# USB0_COMMON_0_VBP2APB_WRAP_CONTROLLER_VBP_CORE_ADDR_MAP register map
Vendor: Texas Instruments
Registers are 32-bit, access per field, reset 0x0 unless marked. A register's access mark holds for its fields unless they carry their own. Offsets are as the file gives them; [hi:lo] are bit positions; {n}, {i} and the like mark numbered series.

## USB0_COMMON_0_VBP2APB_WRAP_CONTROLLER_VBP_CORE_ADDR_MAP (part 5 of 8)
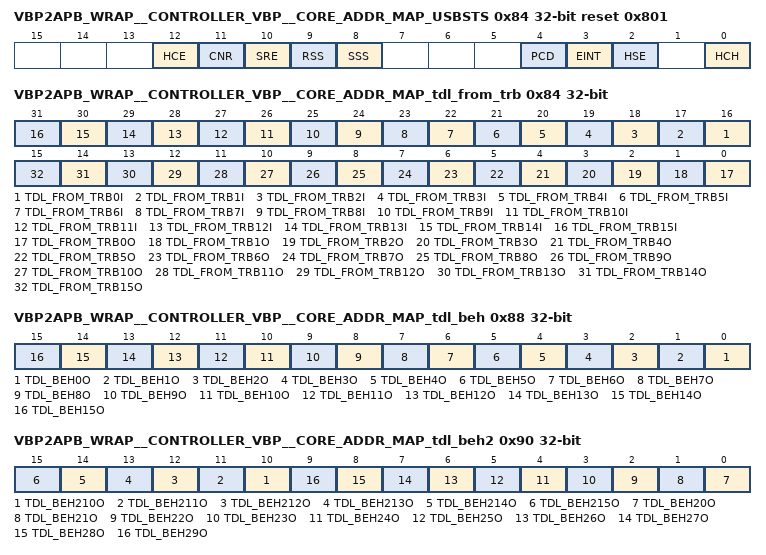
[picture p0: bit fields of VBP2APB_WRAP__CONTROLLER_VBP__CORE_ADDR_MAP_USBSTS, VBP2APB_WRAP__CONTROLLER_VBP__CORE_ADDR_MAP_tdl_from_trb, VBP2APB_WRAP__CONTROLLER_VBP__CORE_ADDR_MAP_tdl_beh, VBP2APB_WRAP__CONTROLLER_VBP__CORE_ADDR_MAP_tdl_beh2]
0x84 VBP2APB_WRAP__CONTROLLER_VBP__CORE_ADDR_MAP_USBSTS access not given reset 0x801
  [12] HCE ro — Host Controller Error [HCE], RO. Default = '0'. '0' = No internal xHC error conditions exist and '1' = Internal xHC error condition. This flag shall be set to indicate that an internal error condition has been detected which requires software to reset and reinitialize the xHC. Refer to section 4.24.1 of xHCI specification for more information.
  [11] CNR ro — Controller Not Ready [CNR], RO. Default = '1'. '0' = Ready and '1' = Not Ready. When this bit is '1', software shall not read or write any register of the xHC, other than those explicitly listed in the Design Specification section titled Register Accessibility. This flag is set by the xHC after a Chip Hardware Reset and cleared when the xHC is ready to begin accepting register reads or writes to all registers. This flag shall remain cleared ['0'] until the next Chip Hardware Reset.
  [10] SRE — Save/Restore Error [SRE], RW1C. Default = '0'. If an error occurs during a Save or Restore operation this bit shall be set to '1'. This bit shall be cleared to '0' when a Save or Restore operation is initiated or when written with '1'. Refer to section 4.23.2 of xHCI specification for more information. When this register is exposed by a Virtual Function [VF], the VMM determines the state of this bit as a function of the Save/Restore completion status for the selected VF. Refer to section 8 of xHCI specification for more information. (access R/W1TC)
  [9] RSS ro — Restore State Status [RSS], RO. Default = '0'. When the Controller Restore State [CRS] flag in the USBCMD register is written with '1' this bit shall be set to '1' and remain '1' while the xHC restores its internal state. When the Restore State operation is complete, this bit shall be cleared to '0'. Refer to section 4.23.2 of xHCI specification for more information. When this register is exposed by a Virtual Function [VF], the VMM determines the state of this bit as a function of the restoring the state for the selected VF. Refer to section 8 of xHCI specification for more information.
  [8] SSS ro — Save State Status [SSS], RO. Default = '0'. When the Controller Save State [CSS] flag in the USBCMD register is written with '1' this bit shall be set to '1' and remain '1' while the xHC saves its internal state. When the Save State operation is complete, this bit shall be cleared to '0'. Refer to section 4.23.2 of xHCI specification for more information. When this register is exposed by a Virtual Function [VF], the VMM determines the state of this bit as a function of the saving the state for the selected VF. Refer to section 8 of xHCI specification for more information.
  [4] PCD — Port Change Detect [PCD], RW1C. Default = '0'. The xHC sets this bit to a '1' when any port has a change bit transition from a '0' to a '1'. This bit is allowed to be maintained in the Aux Power well. Alternatively, it is also acceptable that on a D3 to D0 transition of the xHC, this bit is loaded with the OR of all of the PORTSC change bits. Refer to section 4.19.3 of xHCI specification. This bit provides system software an efficient means of determining if there has been Root Hub port activity. Refer to section 4.15.2.3 of xHCI specification for more information. When this register is exposed by a Virtual Function [VF], the VMM determines the state of this bit as a function of the Root Hub Ports associated with the Device Slots assigned to the selected VF. Refer to section 8 of xHCI specification for more information. (access R/W1TC)
  [3] EINT — Event Interrupt [EINT], RW1C. Default = '0'. The xHC sets this bit to '1' when the Interrupt Pending [IP] bit of any Interrupter transitions from '0' to '1'. Refer to section 7.1.2 of xHCI specification for use. Software that uses EINT shall clear it prior to clearing any IP flags. A race condition may occur if software clears the IP flags then clears the EINT flag, and between the operations another IP '0' to '1' transition occurs. In this case the new IP transition shall be lost. When this register is exposed by a Virtual Function [VF], this bit is the logical 'OR' of the IP bits for the Interrupters assigned to the selected VF. And it shall be cleared to '0' when all associated interrupter IP bits are cleared, i.e. all the VFs Interrupter Event Ring[s] are empty. Refer to section 8 of xHCI specification for more information (access R/W1TC)
  [2] HSE — Host System Error [HSE], RW1C. Default = '0'. The xHC sets this bit to '1' when a serious error is detected, either internal to the xHC or during a host system access involving the xHC module. [In a PCI system, conditions that set this bit to 1 include PCI Parity error, PCI Master Abort, and PCI Target Abort.] When this error occurs, the xHC clears the Run/Stop [R/S] bit in the USBCMD register to prevent further execution of the scheduled TDs. If the HSEE bit in the USBCMD register is a '1', the xHC shall also assert out-of-band error signaling to the host. Refer to section 4.10.2.6 of xHCI specification for more information. When this register is exposed by a Virtual Function [VF], the assertion of this bit affects all VFs and reflects the Host System Error state of the Physical Function [PF0]. Refer to section 8 of xHCI specification for more information. (access R/W1TC)
  [0] HCH ro — HCHalted [HCH], RO. Default = '1'. This bit is a '0' whenever the Run/Stop [R/S] bit is a '1'. The xHC sets this bit to '1' after it has stopped executing as a result of the Run/Stop [R/S] bit being cleared to '0', either by software or by the xHC hardware [e.g. internal error]. If this bit is '1', then SOFs, microSOFs, or Isochronous Timestamp Packets [ITP] shall not be generated by the xHC, and any received Transaction Packet shall be dropped. When this register is exposed by a Virtual Function [VF], this bit only reflects the Halted state of the xHC instance presented by the selected VF. Refer to section 8 of xHCI specification for more information.
0x84 VBP2APB_WRAP__CONTROLLER_VBP__CORE_ADDR_MAP_tdl_from_trb rw
  [n+16] TDL_FROM_TRB{n}I (n=0..15) — This field informs if support for automatic internal TDL calculation basing on the size provided in TRB for DMULT mode is enabled for selected Endpoint. To enable/disable this feature use the ENABLE_TDL_TRB/DISABLE_TDL_TRB bits in the USB_CONF2 register. When this option is enabled the TDL programming with EP_CMD.TDL+STDL is disabled, however read operation through this register can be performed. - 0 - controller doesn't support automatic internal TDL calculation - 1 - controller supports automatic internal TDL calculation This feature can be enabled only when controller supports it, i.e. when the USB_CAP1.TDL_FROM_TRB=1 and when DMULT mode for particular EP is set
  [n] TDL_FROM_TRB{n}O (n=0..15) — This field informs if support for automatic internal TDL calculation basing on the size provided in TRB for DMULT mode is enabled for selected Endpoint. To enable/disable this feature use the ENABLE_TDL_TRB/DISABLE_TDL_TRB bits in the USB_CONF2 register. When this option is enabled the TDL programming with EP_CMD.TDL+STDL is disabled, however read operation through this register can be performed. - 0 - controller doesn't support automatic internal TDL calculation - 1 - controller supports automatic internal TDL calculation This feature can be enabled only when controller supports it, i.e. when the USB_CAP1.TDL_FROM_TRB=1 and when DMULT mode for particular EP is set
0x88 VBP2APB_WRAP__CONTROLLER_VBP__CORE_ADDR_MAP_PAGESIZE ro reset 0x1
  [15:0] PAGESIZE — Page Size, RO. Default = Implementation defined. This field defines the page size supported by the xHC implementation. This xHC supports a page size of 2^[n+12] if bit n is Set. For example, if bit 0 is Set, the xHC supports 4k byte page sizes. For a Virtual Function, this register reflects the page size selected in the System Page Size field of the SR-IOV Extended Capability structure. For the Physical Function 0, this register reflects the implementation dependent default xHC page size. Various xHC resources reference PAGESIZE to describe their minimum alignment requirements. The maximum possible page size is 128M.
0x88 VBP2APB_WRAP__CONTROLLER_VBP__CORE_ADDR_MAP_tdl_beh access not given
  [n] TDL_BEH{n}O rw (n=0..15) — TDL behavior configuration Bit. This register configures TDL behavior for selected Endpoint.
0x8C VBP2APB_WRAP__CONTROLLER_VBP__CORE_ADDR_MAP_DB_ASF_MEM_MASK rw reset 0xFFFFFFFF
  [31:0] DB_ASF_MEM_MASK — Debug Feature. 0-DISABLE/1-ENABLE ECC check for memories
0x8C VBP2APB_WRAP__CONTROLLER_VBP__CORE_ADDR_MAP_RSVDZ8C ro
0x8C VBP2APB_WRAP__CONTROLLER_VBP__CORE_ADDR_MAP_ep_tdl
  [10:0] TDL rw — This field can be used to update/read internal TDL counter when TDL_FROM_TRB mode is not enabled for specific Endpoint.Writing into this field any non-zero value, will result in adding to existing TDL value the new written value. A as the maximum accumulative value of TDL counter is 2047, so when new value is written, and a sum of existing value and new value exceeds 2047, then register is wrap around, e.g. adding value 10 to the existing 2040 will result a value 2 in the TDL register. Writing zero, reset TDL counter to zero. For more information see USBSS-DEV_design_specification document.
0x90 VBP2APB_WRAP__CONTROLLER_VBP__CORE_ADDR_MAP_RSVDZ90 ro
0x90 VBP2APB_WRAP__CONTROLLER_VBP__CORE_ADDR_MAP_tdl_beh2 access not given
  [n-200] TDL_BEH{n}O rw (n=210..215) — TDL behavior 2 configuration Bit. This register configures TDL behavior for selected Endpoint.
  [n-20] TDL_BEH{n}O rw (n=20..29) — TDL behavior 2 configuration Bit. This register configures TDL behavior for selected Endpoint.
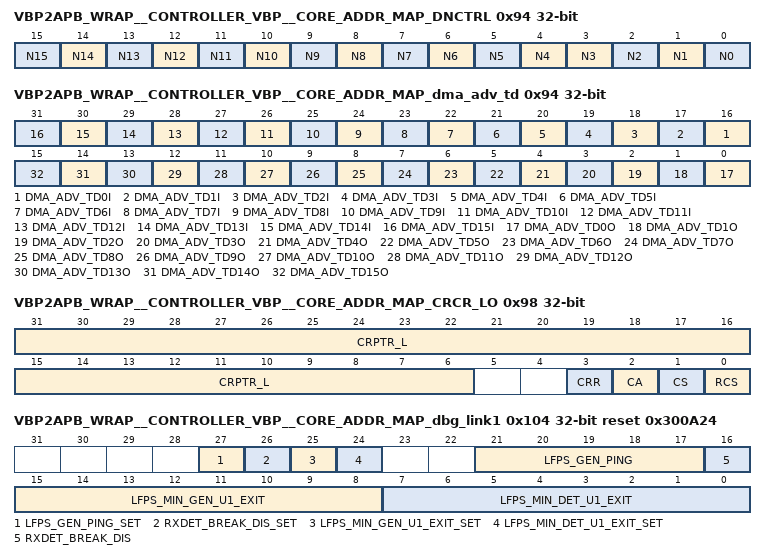
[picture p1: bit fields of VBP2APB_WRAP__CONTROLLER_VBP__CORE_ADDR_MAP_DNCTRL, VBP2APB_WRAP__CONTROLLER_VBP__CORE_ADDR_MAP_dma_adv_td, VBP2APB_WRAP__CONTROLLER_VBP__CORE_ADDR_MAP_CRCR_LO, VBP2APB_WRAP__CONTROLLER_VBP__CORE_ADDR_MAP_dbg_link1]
0x94 VBP2APB_WRAP__CONTROLLER_VBP__CORE_ADDR_MAP_DNCTRL
  [n] N{n} rw (n=4..15) — Notification Enable flag {n}
  [3] N3 rw — Notification Enable flag 3. BUS_INTERVAL_ADJUSTMENT_MESSAGE.
  [2] N2 rw — Notification Enable flag 2. LATENCY_TOLERANCE_MESSAGE.
  [1] N1 rw — Notification Enable flag 1
  [0] N0 rw — Notification Enable flag 0
0x94 VBP2APB_WRAP__CONTROLLER_VBP__CORE_ADDR_MAP_dma_adv_td rw
  [n+16] DMA_ADV_TD{n}I (n=0..15) — DMA Advance TD configuration Register for selected Endpoint.
  [n] DMA_ADV_TD{n}O (n=0..15) — DMA Advance TD configuration Register for selected Endpoint.
0x98 VBP2APB_WRAP__CONTROLLER_VBP__CORE_ADDR_MAP_CRCR_LO access not given
  [31:6] CRPTR_L rw — Command Ring Pointer Low, RW. Default = 0. This field defines low order bits of the initial value of the 64-bit Command Ring Dequeue Pointer. Writes to this field are ignored when Command Ring Running [CRR] = '1'. If the CRCR is written while the Command Ring is stopped [CCR = '0'], the value of this field shall be used to fetch the first Command TRB the next time the Host Controller Doorbell register is written with the DB Reason field set to Host Controller Command. If the CRCR is not written while the Command Ring is stopped [CCR = '0'] then the Command Ring shall begin fetching Command TRBs at the current value of the internal xHC Command Ring Dequeue Pointer. Reading this field always returns zero.
  [3] CRR ro — Command Ring Running [CRR], RO. Default = '0'. This flag is set to '1' if the Run/Stop [R/S] bit is '1' and the Host Controller Doorbell register is written with the DB Reason field set to Host Controller Command. It is cleared to '0' when the Command Ring is stopped after writing a '1' to the Command Stop [CS] or Command Abort [CA] flags, or if the R/S bit is cleared to '0'.
  [2] CA — Command Abort [CA], RW1S. Default = '0'. Writing a '1' to this bit shall immediately terminate the currently executing command, stop the Command Ring, and generate a Command Completion Event with the Completion Code set to Command Ring Stopped. Refer to section 4.6.1.2 of xHCI specification for more information on aborting a command. The next write to the Host Controller Doorbell with DB Reason field set to Host Controller Command shall restart the Command Ring operation. Writes to this flag are ignored by the xHC if Command Ring Running [CRR] = '0'. Reading this bit always returns '0'. (access R/W1TS)
  [1] CS — Command Stop [CS], RW1S. Default = '0'. Writing a '1' to this bit shall stop the operation of the Command Ring after the completion of the currently executing command, and generate a Command Completion Event with the Completion Code set to Command Ring Stopped and the Command TRB Pointer set to the current value of the Command Ring Dequeue Pointer. Refer to section 4.6.1.1 of xHCI specification for more information on stopping a command. The next write to the Host Controller Doorbell with DB Reason field set to Host Controller Command shall restart the Command Ring operation. Writes to this flag are ignored by the xHC if Command Ring Running [CRR] = '0'. Reading this bit shall always return '0'. (access R/W1TS)
  [0] RCS rw — Ring Cycle State [RCS], RW. This bit identifies the value of the xHC Consumer Cycle State [CCS] flag for the TRB referenced by the Command Ring Pointer. Refer to section 4.9.3 of xHCI specification for more information. Writes to this flag are ignored if Command Ring Running [CRR] is '1'. If the CRCR is written while the Command Ring is stopped [CRR = '0'], then the value of this flag shall be used to fetch the first Command TRB the next time the Host Controller Doorbell register is written with the DB Reason field set to Host Controller Command. If the CRCR is not written while the Command Ring is stopped [CRR = '0'], then the Command Ring shall begin fetching Command TRBs using the current value of the internal Command Ring CCS flag. Reading this flag always returns '0'.
0x9C VBP2APB_WRAP__CONTROLLER_VBP__CORE_ADDR_MAP_CRCR_HI rw
  [31:0] CRPTR_H — Command Ring Pointer High, RW. Default = 0. This field defines high order bits of the initial value of the 64-bit Command Ring Dequeue Pointer. Writes to this field are ignored when Command Ring Running [CRR] = '1'. If the CRCR is written while the Command Ring is stopped [CCR = '0'], the value of this field shall be used to fetch the first Command TRB the next time the Host Controller Doorbell register is written with the DB Reason field set to Host Controller Command. If the CRCR is not written while the Command Ring is stopped [CCR = '0'] then the Command Ring shall begin fetching Command TRBs at the current value of the internal xHC Command Ring Dequeue Pointer. Reading this field always returns zero.
0xA0 VBP2APB_WRAP__CONTROLLER_VBP__CORE_ADDR_MAP_RSVDZA0 ro
0xA4 VBP2APB_WRAP__CONTROLLER_VBP__CORE_ADDR_MAP_RSVDZA4 ro
0xA8 VBP2APB_WRAP__CONTROLLER_VBP__CORE_ADDR_MAP_RSVDZA8 ro
0xAC VBP2APB_WRAP__CONTROLLER_VBP__CORE_ADDR_MAP_RSVDZAC ro
0xB0 VBP2APB_WRAP__CONTROLLER_VBP__CORE_ADDR_MAP_DCBAAP_LO
  [31:6] DCBAAPTR_L rw — Device Context Base Address Array Pointer, RW. Default = 0. This field defines low order bits of the 64-bit base address of the Device Context Pointer Array. A table of address pointers that reference Device Context structures for the devices attached to the host.
0xB4 VBP2APB_WRAP__CONTROLLER_VBP__CORE_ADDR_MAP_DCBAAP_HI rw
  [31:0] DCBAAPTR_H — Device Context Base Address Array Pointer, RW. Default = 0. This field defines high order bits of the 64-bit base address of the Device Context Pointer Array. A table of address pointers that reference Device Context structures for the devices attached to the host.
0xB8 VBP2APB_WRAP__CONTROLLER_VBP__CORE_ADDR_MAP_CONFIG
  [7:0] MAXSLOTSEN rw — Max Device Slots Enabled [MaxSlotsEn], RW. Default = 0. This field specifies the maximum number of enabled Device Slots. Valid values are in the range of 0 to MaxSlots. Enabled Devices Slots are allocated contiguously. e.g. A value of 16 specifies that Device Slots 1 to 16 are active. A value of 0 disables all Device Slots. A disabled Device Slot shall not respond to Doorbell Register references. This field shall not be modified by software if the xHC is running [Run/Stop [R/S] = 1].
0xBC VBP2APB_WRAP__CONTROLLER_VBP__CORE_ADDR_MAP_RSVDZBC ro
0xC0 VBP2APB_WRAP__CONTROLLER_VBP__CORE_ADDR_MAP_RSVDZ_OP ro
0x100 VBP2APB_WRAP__CONTROLLER_VBP__CORE_ADDR_MAP_cfg_reg1 reset 0x38000
  [17:0] DEBOUNCER_CNT rw — This parameter defines the VBUS debouncer delay i.e. the time interval between the VBUS detection on device input and the start of using it internally. Resolution of this parameter is 128 ns. For simulation purposes it is recommended to set the value 1 [128ns] For synthesis purposes it is recommended to set the value 230000 [~30ms]
0x104 VBP2APB_WRAP__CONTROLLER_VBP__CORE_ADDR_MAP_dbg_link1 reset 0x300A24
  [27] LFPS_GEN_PING_SET wo — Set the LFPS_GEN_PING_SET value Writing '1' to this bit writes the LFPS_GEN_PING field value to the device. This bit is automatically cleared. Writing '0' has no effect.
  [26] RXDET_BREAK_DIS_SET wo — Set the RXDET_BREAK_DIS value Writing '1' to this bit writes the RXDET_BREAK_DIS field value to the device. This bit is automatically cleared. Writing '0' has no effect.
  [25] LFPS_MIN_GEN_U1_EXIT_SET wo — Set the LFPS_MIN_GEN_U1_EXIT value Writing '1' to this bit writes the LFPS_MIN_GEN_U1_EXIT field value to the device. This bit is automatically cleared. Writing '0' has no effect.
  [24] LFPS_MIN_DET_U1_EXIT_SET wo — Set the LFPS_MIN_DET_U1_EXIT value Writing '1' to this bit writes the LFPS_MIN_DET_U1_EXIT field value to the device. This bit is automatically cleared. Writing '0' has no effect.
  [21:17] LFPS_GEN_PING rw — LFPS_GEN_PING value This parameter configures the LFPS.Ping generation time as shown in the chapter 4. This field is saved to the device only when the field LFPS_GEN_PING_SET is set to '1' during write to the DBG_LINK1 register. Resolution of this parameter is 8 ns. For simulation purposes it is recommended to set the value 24 [~200ns] For synthesis purposes it is recommended to set the value 24 [~200ns]
  [16] RXDET_BREAK_DIS rw — RXDET_BREAK_DIS value This parameter configures terminating the Far-end Receiver termination detection sequence: '0': it is possible that USBSS_DEV will terminate Far-end receiver termination detection sequence '1': USBSS_DEV will not terminate Far-end receiver termination detection sequence The impact of the bit to the link behaviour is shown in chapter 4. This field is saved to the device only when the field RXDET_BREAK_DIS_SET is set to '1' during write to the DBG_LINK1 register.
  [15:8] LFPS_MIN_GEN_U1_EXIT rw — LFPS_MIN_GEN_U1_EXIT value This parameter configures the minimum time for phytxelecidle deassertion when LFPS.U1_Exit signalling is generated as shown in the chapter 4. This field is saved to the device only when the field LFPS_MIN_GEN_U1_EXIT_SET is set to '1' during write to the DBG_LINK1 register. Resolution of this parameter is 8 ns. For simulation purposes it is recommended to set the value 87 [~696ns] For synthesis purposes it is recommended to set the value 87 [~696ns]
  [7:0] LFPS_MIN_DET_U1_EXIT rw — LFPS_MIN_DET_U1_EXIT value This parameter configures the minimum time required for decoding the received LFPS as an LFPS.U1_Exit. Example is shown in the chapter 4. This field is saved to the device only when the field LFPS_MIN_DET_U1_EXIT_SET is set to '1' during write to the DBG_LINK1 register. Resolution of this parameter is 8 ns. For simulation purposes it is recommended to set the value 36 [~300ns]. For synthesis purposes it is recommended to set the value 36 [~300ns].
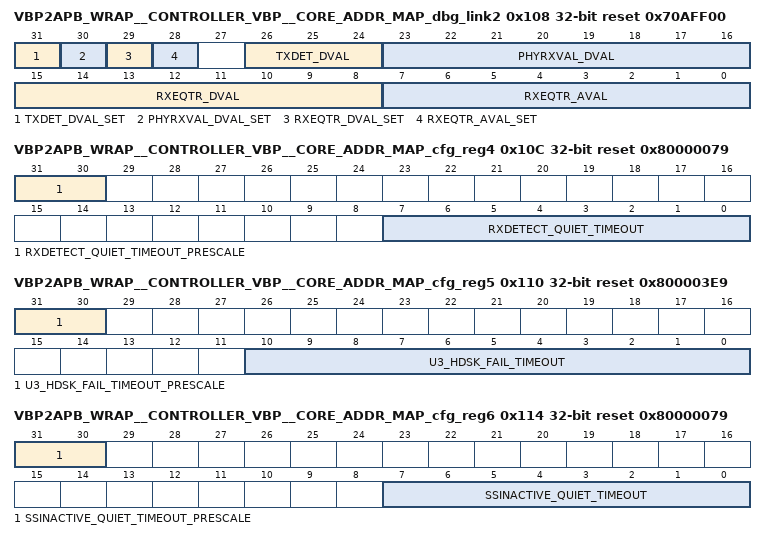
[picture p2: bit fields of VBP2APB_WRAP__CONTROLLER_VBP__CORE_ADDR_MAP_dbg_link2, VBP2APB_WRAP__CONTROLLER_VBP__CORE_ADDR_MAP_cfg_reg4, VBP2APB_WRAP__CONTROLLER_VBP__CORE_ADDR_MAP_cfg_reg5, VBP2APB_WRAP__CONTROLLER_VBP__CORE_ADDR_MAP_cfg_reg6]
0x108 VBP2APB_WRAP__CONTROLLER_VBP__CORE_ADDR_MAP_dbg_link2 reset 0x70AFF00
  [31] TXDET_DVAL_SET wo — Set the TXDET deassertion value Writing '1' to this bit writes the TXDET_DVAL field value to the device. This bit is automatically cleared. Writing '0' has no effect.
  [30] PHYRXVAL_DVAL_SET wo — Set the Phyrxvalid latency deassertion value Writing '1' to this bit writes the PHYRXVAL_DVAL field value to the device. This bit is automatically cleared. Writing '0' has no effect.0
  [29] RXEQTR_DVAL_SET wo — Set the rxeqtraining deassertion value Writing '1' to this bit writes the RXEQTR_DVAL field value to the device. This bit is automatically cleared. Writing '0' has no effect.
  [28] RXEQTR_AVAL_SET wo — Set the rxeqtraining assertion value Writing '1' to this bit writes the RXEQTR_AVAL field value to the device. This bit is automatically cleared. Writing '0' has no effect.
  [26:24] TXDET_DVAL rw — TXDET deassertion value This parameter configures the phytxdetrx_loop deassertion time after phystatus deassertion during Far-end receiver termination sequence as shown in the chapter 4. This field is saved to the device only when the field TXDET_DVAL_SET is set to '1' during write to the DBG_LINK2 register.
  [23:16] PHYRXVAL_DVAL rw — Phyrxvalid latency deassertion value This parameter enables extending internal phyrxdata and phyrxdatak validity as shown in the chapter 4. This field is saved to the device only when the field PHYRXVAL_DVAL_SET is set to '1' during write to the DBG_LINK2 register.
  [15:8] RXEQTR_DVAL rw — Rxeqtraining deassertion value This parameter configures phyrxeqtraining deasserting time as shown in the chapter 4. This field is saved to the device only when the field RXEQTR_DVAL_SET is set to '1' during write to the DBG_LINK2 register.
  [7:0] RXEQTR_AVAL rw — Rxeqtraining assertion value This parameter configures phyrxeqtraining asserting time as shown in the chapter 4. This field is saved to the device only when the field RXEQTR_AVAL_SET is set to '1' during write to the DBG_LINK2 register.
0x10C VBP2APB_WRAP__CONTROLLER_VBP__CORE_ADDR_MAP_cfg_reg4 reset 0x80000079
  [31:30] RXDETECT_QUIET_TIMEOUT_PRESCALE rw — PRESCALER for RXDETECT_QUIET_TIMEOUT : - 0x0 : 8ns [PHY pclk clock] - 0x1 : 1us - 0x2 : 100us - 0x3 : no clock - allows disabling certain timeout
  [7:0] RXDETECT_QUIET_TIMEOUT rw — RXDETECT_QUIET_TIMEOUT value Resolution of this parameter is selected by RXDETECT_QUIET_TIMEOUT_PRESCALE. For simulation purposes it is recommended to set the value: - 11*100us =~1ms [SystemC device ENV] - 13*1us =~12us [VIP based ENV] For synthesis purposes it is recommended to set the value 121*100us =~12ms
0x110 VBP2APB_WRAP__CONTROLLER_VBP__CORE_ADDR_MAP_cfg_reg5 reset 0x800003E9
  [31:30] U3_HDSK_FAIL_TIMEOUT_PRESCALE rw — PRESCALER for U3_HDSK_FAIL_TIMEOUT : - 0x0 : 8ns [PHY pclk clock] - 0x1 : 1us - 0x2 : 100us - 0x3 : no clock - allows disabling certain timeout
  [10:0] U3_HDSK_FAIL_TIMEOUT rw — U3_HDSK_FAIL_TIMEOUT value Resolution of this parameter is selected by U3_HDSK_FAIL_TIMEOUT_PRESCALE. For simulation purposes it is recommended to set the value: - 11*100us =~1ms [SystemC device ENV] - 11*100us =~1ms [VIP based ENV] For synthesis purposes it is recommended to set the value 1001*100us =~100ms
0x114 VBP2APB_WRAP__CONTROLLER_VBP__CORE_ADDR_MAP_cfg_reg6 reset 0x80000079
  [31:30] SSINACTIVE_QUIET_TIMEOUT_PRESCALE rw — PRESCALER for SSINACTIVE_QUIET_TIMEOUT value: - 0x0 : 8ns [PHY pclk clock] - 0x1 : 1us - 0x2 : 100us - 0x3 : no clock - allows disabling certain timeout
  [7:0] SSINACTIVE_QUIET_TIMEOUT rw — SSINACTIVE_QUIET_TIMEOUT value Resolution of this parameter is selected by SSINACTIVE_QUIET_TIMEOUT_PRESCALE. For simulation purposes it is recommended to set the value: - 11*100us =~1ms [SystemC device ENV] - 13*1us =~12us [VIP based ENV] For synthesis purposes it is recommended to set the value: - 121*100us =~12ms
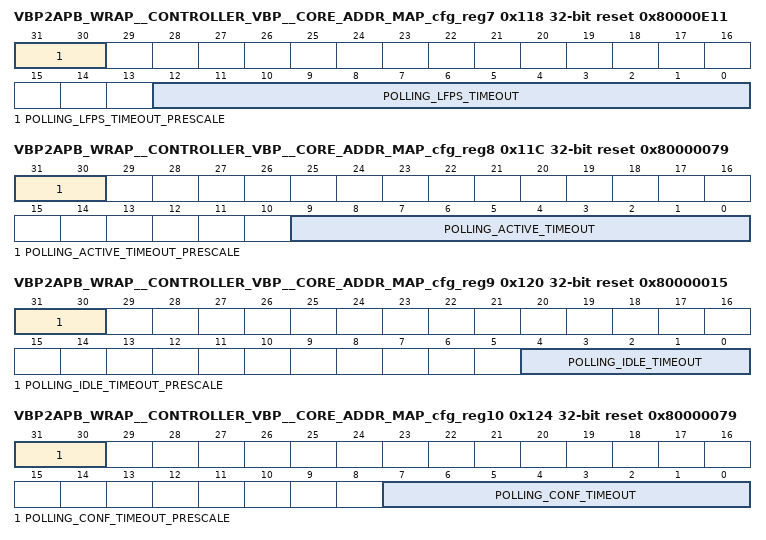
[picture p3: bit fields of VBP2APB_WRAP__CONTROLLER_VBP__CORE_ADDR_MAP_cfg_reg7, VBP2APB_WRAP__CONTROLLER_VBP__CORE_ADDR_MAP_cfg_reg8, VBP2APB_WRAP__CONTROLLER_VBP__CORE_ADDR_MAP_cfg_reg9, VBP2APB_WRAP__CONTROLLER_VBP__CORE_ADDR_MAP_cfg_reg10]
0x118 VBP2APB_WRAP__CONTROLLER_VBP__CORE_ADDR_MAP_cfg_reg7 reset 0x80000E11
  [31:30] POLLING_LFPS_TIMEOUT_PRESCALE rw — PRESCALER for POLLING_LFPS_TIMEOUT value: - 0x0 : 8ns [PHY pclk clock] - 0x1 : 1us - 0x2 : 100us - 0x3 : no clock - allows disabling certain timeout
  [12:0] POLLING_LFPS_TIMEOUT rw — POLLING_LFPS_TIMEOUT value Resolution of this parameter is selected by POLLING_LFPS_TIMEOUT_PRESCALE. For simulation purposes it is recommended to set the value: - 11*100us =~1ms [SystemC device ENV] - 481*1us =~480us [VIP based ENV] For synthesis purposes it is recommended to set the value: - 3601*100us =~360ms
0x11C VBP2APB_WRAP__CONTROLLER_VBP__CORE_ADDR_MAP_cfg_reg8 reset 0x80000079
  [31:30] POLLING_ACTIVE_TIMEOUT_PRESCALE rw — PRESCALER for POLLING_ACTIVE_TIMEOUT value: - 0x0 : 8ns [PHY pclk clock] - 0x1 : 1us - 0x2 : 100us - 0x3 : no clock - allows disabling certain timeout
  [9:0] POLLING_ACTIVE_TIMEOUT rw — POLLING_ACTIVE_TIMEOUT value Resolution of this parameter is selected by POLLING_ACTIVE_TIMEOUT_PRESCALE. For simulation purposes it is recommended to set the value: - 11*100us =~1ms [SystemC device ENV] - 31*1us =~30us [VIP based ENV] For synthesis purposes it is recommended to set the value: - 121*100us =~12ms
0x120 VBP2APB_WRAP__CONTROLLER_VBP__CORE_ADDR_MAP_cfg_reg9 reset 0x80000015
  [31:30] POLLING_IDLE_TIMEOUT_PRESCALE rw — PRESCALER for POLLING_IDLE_TIMEOUT value: - 0x0 : 8ns [PHY pclk clock] - 0x1 : 1us - 0x2 : 100us - 0x3 : no clock - allows disabling certain timeout
  [4:0] POLLING_IDLE_TIMEOUT rw — POLLING_IDLE_TIMEOUT value Resolution of this parameter is selected by POLLING_IDLE_TIMEOUT_PRESCALE. For simulation purposes it is recommended to set the value: - 21*100us =~2ms [SystemC device ENV] - 3*1us =~2us [VIP based ENV] For synthesis purposes it is recommended to set the value: - 21*100us =~2ms
0x124 VBP2APB_WRAP__CONTROLLER_VBP__CORE_ADDR_MAP_cfg_reg10 reset 0x80000079
  [31:30] POLLING_CONF_TIMEOUT_PRESCALE rw — PRESCALER for POLLING_CONF_TIMEOUT value: - 0x0 : 8ns [PHY pclk clock] - 0x1 : 1us - 0x2 : 100us - 0x3 : no clock - allows disabling certain timeout
  [7:0] POLLING_CONF_TIMEOUT rw — POLLING_CONF_TIMEOUT value Resolution of this parameter is selected by POLLING_CONF_TIMEOUT_PRESCALE. For simulation purposes it is recommended to set the value: - 11*100us =~1ms [SystemC device ENV] - 31*1us =~30us [VIP based ENV] For synthesis purposes it is recommended to set the value: - 121*100us =~12ms
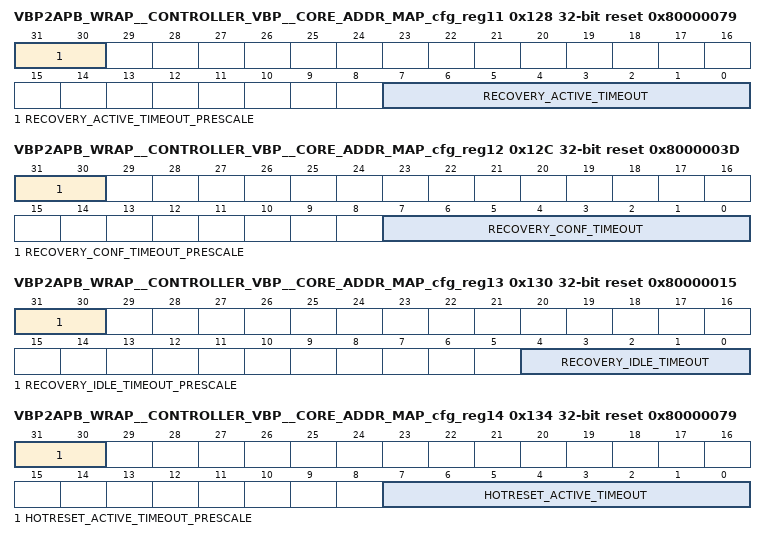
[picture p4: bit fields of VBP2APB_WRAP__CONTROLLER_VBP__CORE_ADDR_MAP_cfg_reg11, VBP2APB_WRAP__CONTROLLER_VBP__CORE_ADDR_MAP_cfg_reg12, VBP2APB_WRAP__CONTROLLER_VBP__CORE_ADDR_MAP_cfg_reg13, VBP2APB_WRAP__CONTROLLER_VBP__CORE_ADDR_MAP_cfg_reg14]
0x128 VBP2APB_WRAP__CONTROLLER_VBP__CORE_ADDR_MAP_cfg_reg11 reset 0x80000079
  [31:30] RECOVERY_ACTIVE_TIMEOUT_PRESCALE rw — PRESCALER for RECOVERY_ACTIVE_TIMEOUT value: - 0x0 : 8ns [PHY pclk clock] - 0x1 : 1us - 0x2 : 100us - 0x3 : no clock - allows disabling certain timeout
  [7:0] RECOVERY_ACTIVE_TIMEOUT rw — RECOVERY_ACTIVE_TIMEOUT value Resolution of this parameter is selected by RECOVERY_ACTIVE_TIMEOUT_PRESCALE. For simulation purposes it is recommended to set the value: - 11*100us =~1ms [SystemC device ENV] - 101*1us =~100us [VIP based ENV] For synthesis purposes it is recommended to set the value: - 121*100us =~12ms
0x12C VBP2APB_WRAP__CONTROLLER_VBP__CORE_ADDR_MAP_cfg_reg12 reset 0x8000003D
  [31:30] RECOVERY_CONF_TIMEOUT_PRESCALE rw — PRESCALER for RECOVERY_CONF_TIMEOUT value: - 0x0 : 8ns [PHY pclk clock] - 0x1 : 1us - 0x2 : 100us - 0x3 : no clock - allows disabling certain timeout
  [7:0] RECOVERY_CONF_TIMEOUT rw — RECOVERY_CONF_TIMEOUT value Resolution of this parameter is selected by RECOVERY_CONF_TIMEOUT_PRESCALE. For simulation purposes it is recommended to set the value: - 11*100us =~1ms [SystemC device ENV] - 101*1us =~100us [VIP based ENV] For synthesis purposes it is recommended to set the value: - 61*100us =~6ms
0x130 VBP2APB_WRAP__CONTROLLER_VBP__CORE_ADDR_MAP_cfg_reg13 reset 0x80000015
  [31:30] RECOVERY_IDLE_TIMEOUT_PRESCALE rw — PRESCALER for RECOVERY_IDLE_TIMEOUT value: - 0x0 : 8ns [PHY pclk clock] - 0x1 : 1us - 0x2 : 100us - 0x3 : no clock - allows disabling certain timeout
  [4:0] RECOVERY_IDLE_TIMEOUT rw — RECOVERY_IDLE_TIMEOUT value Resolution of this parameter is selected by RECOVERY_IDLE_TIMEOUT_PRESCALE. For simulation purposes it is recommended to set the value: - 21*100us =~2ms [SystemC device ENV] - 3*1us =~3us [VIP based ENV] For synthesis purposes it is recommended to set the value: - 21*100us =~2ms
0x134 VBP2APB_WRAP__CONTROLLER_VBP__CORE_ADDR_MAP_cfg_reg14 reset 0x80000079
  [31:30] HOTRESET_ACTIVE_TIMEOUT_PRESCALE rw — PRESCALER for HOTRESET_ACTIVE_TIMEOUT value: - 0x0 : 8ns [PHY pclk clock] - 0x1 : 1us - 0x2 : 100us - 0x3 : no clock - allows disabling certain timeout
  [7:0] HOTRESET_ACTIVE_TIMEOUT rw — HOTRESET_ACTIVE_TIMEOUT value Resolution of this parameter is selected by HOTRESET_ACTIVE_TIMEOUT_PRESCALE. For simulation purposes it is recommended to set the value: - 21*100us =~2ms [SystemC device ENV] - 13*1us =~13us [VIP based ENV] For synthesis purposes it is recommended to set the value: - 121*100us =~12ms
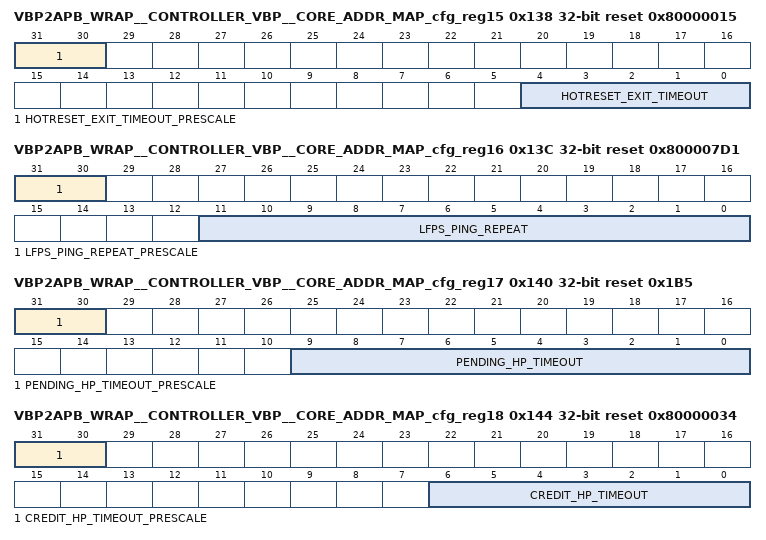
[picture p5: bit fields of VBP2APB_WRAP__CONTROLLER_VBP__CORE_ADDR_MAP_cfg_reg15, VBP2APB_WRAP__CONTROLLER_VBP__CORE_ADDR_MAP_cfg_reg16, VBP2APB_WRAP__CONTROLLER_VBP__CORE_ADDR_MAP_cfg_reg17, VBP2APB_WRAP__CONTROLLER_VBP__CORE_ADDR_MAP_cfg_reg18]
0x138 VBP2APB_WRAP__CONTROLLER_VBP__CORE_ADDR_MAP_cfg_reg15 reset 0x80000015
  [31:30] HOTRESET_EXIT_TIMEOUT_PRESCALE rw — PRESCALER for HOTRESET_EXIT_TIMEOUT value: - 0x0 : 8ns [PHY pclk clock] - 0x1 : 1us - 0x2 : 100us - 0x3 : no clock - allows disabling certain timeout
  [4:0] HOTRESET_EXIT_TIMEOUT rw — HOTRESET_EXIT_TIMEOUT value Resolution of this parameter is selected by HOTRESET_EXIT_TIMEOUT_PRESCALE. For simulation purposes it is recommended to set the value: - 21*100us =~2ms [SystemC device ENV] - 3*1us =~3us [VIP based ENV] For synthesis purposes it is recommended to set the value: - 21*100us =~2ms
0x13C VBP2APB_WRAP__CONTROLLER_VBP__CORE_ADDR_MAP_cfg_reg16 reset 0x800007D1
  [31:30] LFPS_PING_REPEAT_PRESCALE rw — PRESCALER for LFPS_PING_REPEAT value: - 0x0 : 8ns [PHY pclk clock] - 0x1 : 1us - 0x2 : 100us - 0x3 : no clock - allows disabling certain timeout
  [11:0] LFPS_PING_REPEAT rw — LFPS_PING_REPEAT value Resolution of this parameter is selected by LFPS_PING_REPEAT_PRESCALE. For simulation purposes it is recommended to set the value: - 6*100us =~0.5ms [SystemC device ENV] - 4*100us =~400us [VIP based ENV] For synthesis purposes it is recommended to set the value: - 2001*100us =~200ms
0x140 VBP2APB_WRAP__CONTROLLER_VBP__CORE_ADDR_MAP_cfg_reg17 reset 0x1B5
  [31:30] PENDING_HP_TIMEOUT_PRESCALE rw — PRESCALER for PENDING_HP_TIMEOUT value: - 0x0 : 8ns [PHY pclk clock] - 0x1 : 1us - 0x2 : 100us - 0x3 : no clock - allows disabling certain timeout
  [9:0] PENDING_HP_TIMEOUT rw — PENDING_HP_TIMEOUT value Resolution of this parameter is selected by PENDING_HP_TIMEOUT_PRESCALE. For simulation purposes it is recommended to set the value: - 437*8ns =~3.5us [SystemC device ENV] - 437*8ns =~3.5us [VIP based ENV] For synthesis purposes it is recommended to set the value: - 437*8ns =~3.5us
0x144 VBP2APB_WRAP__CONTROLLER_VBP__CORE_ADDR_MAP_cfg_reg18 reset 0x80000034
  [31:30] CREDIT_HP_TIMEOUT_PRESCALE rw — PRESCALER for CREDIT_HP_TIMEOUT value: - 0x0 : 8ns [PHY pclk clock] - 0x1 : 1us - 0x2 : 100us - 0x3 : no clock - allows disabling certain timeout
  [6:0] CREDIT_HP_TIMEOUT rw — CREDIT_HP_TIMEOUT value Resolution of this parameter is selected by CREDIT_HP_TIMEOUT_PRESCALE. For simulation purposes it is recommended to set the value: - 11*100us =~1ms [SystemC device ENV] - 11*100us =~1ms [VIP based ENV] For synthesis purposes it is recommended to set the value: - 52*100us =~5.1ms
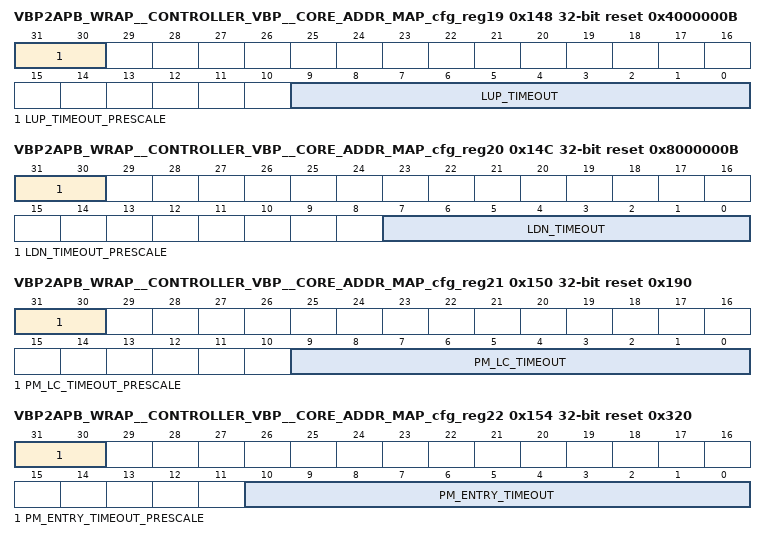
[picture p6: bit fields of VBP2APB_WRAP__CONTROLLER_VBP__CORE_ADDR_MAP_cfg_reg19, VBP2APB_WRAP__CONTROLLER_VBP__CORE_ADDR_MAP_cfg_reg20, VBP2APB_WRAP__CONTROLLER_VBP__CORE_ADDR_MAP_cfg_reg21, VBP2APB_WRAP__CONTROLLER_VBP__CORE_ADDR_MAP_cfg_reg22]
0x148 VBP2APB_WRAP__CONTROLLER_VBP__CORE_ADDR_MAP_cfg_reg19 reset 0x4000000B
  [31:30] LUP_TIMEOUT_PRESCALE rw — PRESCALER for LUP_TIMEOUT value: - 0x0 : 8ns [PHY pclk clock] - 0x1 : 1us - 0x2 : 100us - 0x3 : no clock - allows disabling certain timeout
  [9:0] LUP_TIMEOUT rw — LUP_TIMEOUT value Resolution of this parameter is selected by LUP_TIMEOUT_PRESCALE. For simulation purposes it is recommended to set the value: - 11*1us =~11us [SystemC device ENV] - 11*1us =~11us [VIP based ENV] For synthesis purposes it is recommended to set the value: - 11*1us =~11us
0x14C VBP2APB_WRAP__CONTROLLER_VBP__CORE_ADDR_MAP_cfg_reg20 reset 0x8000000B
  [31:30] LDN_TIMEOUT_PRESCALE rw — PRESCALER for LDN_TIMEOUT value: - 0x0 : 8ns [PHY pclk clock] - 0x1 : 1us - 0x2 : 100us - 0x3 : no clock - allows disabling certain timeout
  [7:0] LDN_TIMEOUT rw — LDN_TIMEOUT value Resolution of this parameter is selected by LDN_TIMEOUT_PRESCALE. For simulation purposes it is recommended to set the value: - 11*100us =~1ms [SystemC device ENV] - 129*1us =~129us [VIP based ENV] For synthesis purposes it is recommended to set the value: - 11*100us =~1ms
0x150 VBP2APB_WRAP__CONTROLLER_VBP__CORE_ADDR_MAP_cfg_reg21 reset 0x190
  [31:30] PM_LC_TIMEOUT_PRESCALE rw — PRESCALER for PM_LC_TIMEOUT value: - 0x0 : 8ns [PHY pclk clock] - 0x1 : 1us - 0x2 : 100us - 0x3 : no clock - allows disabling certain timeout
  [9:0] PM_LC_TIMEOUT rw — PM_LC_TIMEOUT value Resolution of this parameter is selected by PM_LC_TIMEOUT_PRESCALE. For simulation purposes it is recommended to set the value: - 400*8ns =~3.2us [SystemC device ENV] - 400*8ns =~3.2us [VIP based ENV] For synthesis purposes it is recommended to set the value: - 400*8ns =~3.2us
0x154 VBP2APB_WRAP__CONTROLLER_VBP__CORE_ADDR_MAP_cfg_reg22 reset 0x320
  [31:30] PM_ENTRY_TIMEOUT_PRESCALE rw — PRESCALER for PM_ENTRY_TIMEOUT value: - 0x0 : 8ns [PHY pclk clock] - 0x1 : 1us - 0x2 : 100us - 0x3 : no clock - allows disabling certain timeout
  [10:0] PM_ENTRY_TIMEOUT rw — PM_ENTRY_TIMEOUT value Resolution of this parameter is selected by PM_ENTRY_TIMEOUT_PRESCALE. For simulation purposes it is recommended to set the value: - 800*8ns =~6.4us [SystemC device ENV] - 800*8ns =~6.4us [VIP based ENV] For synthesis purposes it is recommended to set the value: - 800*8ns =~6.4us
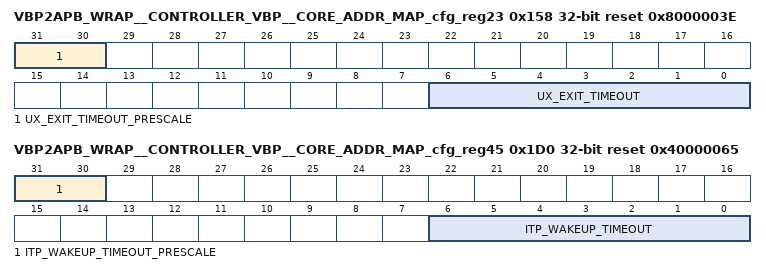
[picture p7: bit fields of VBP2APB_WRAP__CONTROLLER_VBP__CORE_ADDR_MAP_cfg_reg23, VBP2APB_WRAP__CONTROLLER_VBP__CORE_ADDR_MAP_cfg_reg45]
0x158 VBP2APB_WRAP__CONTROLLER_VBP__CORE_ADDR_MAP_cfg_reg23 reset 0x8000003E
  [31:30] UX_EXIT_TIMEOUT_PRESCALE rw — PRESCALER for UX_EXIT_TIMEOUT value: - 0x0 : 8ns [PHY pclk clock] - 0x1 : 1us - 0x2 : 100us - 0x3 : no clock - allows disabling certain timeout
  [6:0] UX_EXIT_TIMEOUT rw — UX_EXIT_TIMEOUT value Resolution of this parameter is selected by UX_EXIT_TIMEOUT_PRESCALE. For simulation purposes it is recommended to set the value: - 8*100us =~800us [SystemC device ENV] - 3*100us =~300us [VIP based ENV] For synthesis purposes it is recommended to set the value: - 62*100us =~6.2ms
0x15C VBP2APB_WRAP__CONTROLLER_VBP__CORE_ADDR_MAP_cfg_reg24 reset 0x243D58
  [22:0] LFPS_DET_RESET_MIN rw — LFPS_DET_RESET_MIN value Resolution of this parameter is 8 ns. For simulation purposes it is recommended to set the value 395833 [~3.16ms] For synthesis purposes it is recommended to set the value 2375000 [~19ms]
0x160 VBP2APB_WRAP__CONTROLLER_VBP__CORE_ADDR_MAP_cfg_reg25 reset 0xE4E1C0
  [23:0] LFPS_DET_RESET_MAX rw — LFPS_DET_RESET_MAX value Resolution of this parameter is 8 ns. For simulation purposes it is recommended to set the value 5000000 [~40ms] For synthesis purposes it is recommended to set the value 15000000 [~120ms]
0x164 VBP2APB_WRAP__CONTROLLER_VBP__CORE_ADDR_MAP_cfg_reg26 reset 0x4B
  [6:0] LFPS_DET_POLLING_MIN rw — LFPS_DET_POLLING_MIN value Resolution of this parameter is 8 ns. For simulation purposes it is recommended to set the value 75 [~0.6us] For synthesis purposes it is recommended to set the value 75 [~0.6us]
0x168 VBP2APB_WRAP__CONTROLLER_VBP__CORE_ADDR_MAP_cfg_reg27 reset 0xBB
  [7:0] LFPS_DET_POLLING_MAX rw — LFPS_DET_POLLING_MAX value Resolution of this parameter is 8 ns. For simulation purposes it is recommended to set the value 175 [~1.4us] For synthesis purposes it is recommended to set the value 175 [~1.4us]
0x16C VBP2APB_WRAP__CONTROLLER_VBP__CORE_ADDR_MAP_cfg_reg28 reset 0x4
  [2:0] LFPS_DET_PING_MIN rw — LFPS_DET_PING_MIN value Resolution of this parameter is 8 ns. For simulation purposes it is recommended to set the value 4 [~40ns] For synthesis purposes it is recommended to set the value 4 [~40ns]
0x170 VBP2APB_WRAP__CONTROLLER_VBP__CORE_ADDR_MAP_cfg_reg29 reset 0x17
  [4:0] LFPS_DET_PING_MAX rw — LFPS_DET_PING_MAX value Resolution of this parameter is 8 ns. For simulation purposes it is recommended to set the value 23 [~200ns] For synthesis purposes it is recommended to set the value 23 [~200ns]
0x174 VBP2APB_WRAP__CONTROLLER_VBP__CORE_ADDR_MAP_cfg_reg30 reset 0x24
  [5:0] LFPS_DET_U1EXIT_MIN rw — LFPS_DET_U1EXIT_MIN value Resolution of this parameter is 8 ns. For simulation purposes it is recommended to set the value 36 [~300ns] For synthesis purposes it is recommended to set the value 36 [~300ns]
0x178 VBP2APB_WRAP__CONTROLLER_VBP__CORE_ADDR_MAP_cfg_reg31 reset 0x6F
  [6:0] LFPS_DET_U1EXIT_MAX rw — LFPS_DET_U1EXIT_MAX value Resolution of this parameter is 8 ns. For simulation purposes it is recommended to set the value 111 [~900ns] For synthesis purposes it is recommended to set the value 111 [~900ns]
0x17C VBP2APB_WRAP__CONTROLLER_VBP__CORE_ADDR_MAP_cfg_reg32 reset 0x24
  [5:0] LFPS_DET_U2EXIT_MIN rw — LFPS_DET_U2EXIT_MIN value Resolution of this parameter is 8 ns. For simulation purposes it is recommended to set the value 36 [~300ns] For synthesis purposes it is recommended to set the value 36 [~300ns]
0x180 VBP2APB_WRAP__CONTROLLER_VBP__CORE_ADDR_MAP_cfg_reg33 reset 0x3D090
  [17:0] LFPS_DET_U2EXIT_MAX rw — LFPS_DET_U2EXIT_MAX value Resolution of this parameter is 8 ns. For simulation purposes it is recommended to set the value 250000 [~2ms] For synthesis purposes it is recommended to set the value 250000 [~2ms]
0x184 VBP2APB_WRAP__CONTROLLER_VBP__CORE_ADDR_MAP_cfg_reg34 reset 0x24
  [5:0] LFPS_DET_U3EXIT_MIN rw — LFPS_DET_U3EXIT_MIN value Resolution of this parameter is 8 ns. For simulation purposes it is recommended to set the value 36 [~300ns] For synthesis purposes it is recommended to set the value 36 [~300ns]
0x188 VBP2APB_WRAP__CONTROLLER_VBP__CORE_ADDR_MAP_cfg_reg35 reset 0x1312D0
  [20:0] LFPS_DET_U3EXIT_MAX rw — LFPS_DET_U3EXIT_MAX value Resolution of this parameter is 8 ns. For simulation purposes it is recommended to set the value 1250000 [~10ms] For synthesis purposes it is recommended to set the value 1250000 [~10ms]
0x1AC VBP2APB_WRAP__CONTROLLER_VBP__CORE_ADDR_MAP_cfg_reg36 reset 0x18
  [4:0] LFPS_GEN_PING rw — LFPS_GEN_PING value Resolution of this parameter is 8 ns. For simulation purposes it is recommended to set the value 24 [~200ns] For synthesis purposes it is recommended to set the value 24 [~200ns]
0x1B0 VBP2APB_WRAP__CONTROLLER_VBP__CORE_ADDR_MAP_cfg_reg37 reset 0x7D
  [7:0] LFPS_GEN_POLLING rw — LFPS_GEN_POLLING value Resolution of this parameter is 8 ns. For simulation purposes it is recommended to set the value 125 [~1us] For synthesis purposes it is recommended to set the value 125 [~1us]
0x1B4 VBP2APB_WRAP__CONTROLLER_VBP__CORE_ADDR_MAP_cfg_reg38 reset 0x3D090
  [17:0] LFPS_GEN_U1EXIT rw — LFPS_GEN_U1EXIT value Resolution of this parameter is 8 ns. For simulation purposes it is recommended to set the value 62500 [~500us] For synthesis purposes it is recommended to set the value 250000 [~2ms]
0x1B8 VBP2APB_WRAP__CONTROLLER_VBP__CORE_ADDR_MAP_cfg_reg39 reset 0x1312D0
  [20:0] LFPS_GEN_U3EXIT rw — LFPS_GEN_U3EXIT value Resolution of this parameter is 8 ns. For simulation purposes it is recommended to set the value 125000 [~1ms] For synthesis purposes it is recommended to set the value 1250000 [~10ms]
0x1BC VBP2APB_WRAP__CONTROLLER_VBP__CORE_ADDR_MAP_cfg_reg40 reset 0x1F
  [6:0] LFPS_MIN_GEN_U1EXIT rw — LFPS_MIN_GEN_U1EXIT value Resolution of this parameter is 8 ns. For simulation purposes it is recommended to set the value 87 [~696ns] For synthesis purposes it is recommended to set the value 87 [~696ns]
0x1C0 VBP2APB_WRAP__CONTROLLER_VBP__CORE_ADDR_MAP_cfg_reg41 reset 0x30D4
  [14:0] LFPS_MIN_GEN_U2EXIT rw — LFPS_MIN_GEN_U2EXIT value Resolution of this parameter is 8 ns. For simulation purposes it is recommended to set the value 12500 [~100us] For synthesis purposes it is recommended to set the value 12500 [~100us]
0x1C4 VBP2APB_WRAP__CONTROLLER_VBP__CORE_ADDR_MAP_cfg_reg42 reset 0x4E2
  [10:0] LFPS_POLLING_REPEAT rw — LFPS_POLLING_REPEAT value Resolution of this parameter is 8 ns. For simulation purposes it is recommended to set the value 1250 [~10us] For synthesis purposes it is recommended to set the value 1250 [~10us]
0x1C8 VBP2APB_WRAP__CONTROLLER_VBP__CORE_ADDR_MAP_cfg_reg43 reset 0x6D6
  [10:0] LFPS_POLLING_MAX_TREPEAT rw — LFPS_POLLING_MAX_TREPEAT value Resolution of this parameter is 8 ns. For simulation purposes it is recommended to set the value 1750 [~14us] For synthesis purposes it is recommended to set the value 1750 [~14us]
0x1CC VBP2APB_WRAP__CONTROLLER_VBP__CORE_ADDR_MAP_cfg_reg44 reset 0x2EC
  [10:0] LFPS_POLLING_MIN_TREPEAT rw — LFPS_POLLING_MIN_TREPEAT value Resolution of this parameter is 8 ns. For simulation purposes it is recommended to set the value 748 [~6us] For synthesis purposes it is recommended to set the value 748 [~6us]
0x1D0 VBP2APB_WRAP__CONTROLLER_VBP__CORE_ADDR_MAP_cfg_reg45 reset 0x40000065
  [31:30] ITP_WAKEUP_TIMEOUT_PRESCALE rw — PRESCALER for ITP_WAKEUP_TIMEOUT value: - 0x0 : 8ns [PHY pclk clock] - 0x1 : 1us - 0x2 : 100us - 0x3 : no clock - allows disabling certain timeout
  [6:0] ITP_WAKEUP_TIMEOUT rw — ITP_WAKEUP_TIMEOUT value Resolution of this parameter is selected by ITP_WAKEUP_TIMEOUT_PRESCALE. For simulation purposes it is recommended to set the value: - 101*1us =~100us [SystemC device ENV] - 101*1us =~100us [VIP based ENV] For synthesis purposes it is recommended to set the value: - 101*1us =~100us
0x1D4 VBP2APB_WRAP__CONTROLLER_VBP__CORE_ADDR_MAP_cfg_reg46 reset 0xFFFF
  [15:0] TSEQ_QUANTITY rw — TSEQ_QUANTITY value This parameter defines the number of TSEQ training sequences to be sent during Polling.RxEq state. For simulation purposes it is recommended to set the value 655 For synthesis purposes it is recommended to set the value 65535.
0x1D8 VBP2APB_WRAP__CONTROLLER_VBP__CORE_ADDR_MAP_cfg_reg47 reset 0x7D001
  [19:0] ERDY_TIMEOUT_CNT rw — ERDY_TIMEOUT_CNT value Resolution of this parameter is 1 us. For simulation purposes it is recommended to set the value 16 [~15 us] For synthesis purposes it is recommended to set the value ~512001 [~512ms]
0x1DC VBP2APB_WRAP__CONTROLLER_VBP__CORE_ADDR_MAP_cfg_reg48 reset 0x18000
  [17:0] TWTRSTFS_J_CNT rw — Time a device operating in full speed must wait before begin the transition to the Suspend state after it see a constant Idle state on their upstream facing bus lines. Resolution of this parameter is 33.3 ns. For simulation purposes it is recommended to set the value 98304 [~3.28ms] For synthesis purposes it is recommended to set the value 98304 [~3.28ms]
0x1E0 VBP2APB_WRAP__CONTROLLER_VBP__CORE_ADDR_MAP_cfg_reg49 reset 0x8B00
  [15:0] TUCH_CNT rw — TUCH: Minimum duration of a Chirp K from a high-speed capable device within the reset protocol. Resolution of this parameter is 33.3 ns. For simulation purposes it is recommended to set the value 129 [~4.3us] For synthesis purposes it is recommended to set the value 35584 [~1.19ms]
0x1E4 VBP2APB_WRAP__CONTROLLER_VBP__CORE_ADDR_MAP_cfg_reg50 reset 0x960
  [11:0] TWAITCHK_CNT rw — Time to wait before device will start to drive Chirp K after detecting reset signalling. Resolution of this parameter is 33.3 ns. For simulation purposes it is recommended to set the value 30 [~1us] For synthesis purposes it is recommended to set the value 2400 [~80us]
0x1E8 VBP2APB_WRAP__CONTROLLER_VBP__CORE_ADDR_MAP_cfg_reg51 reset 0x19A03
  [16:0] TWTFS_CNT rw — TWTFS: Time after end of upstream chirp at which device reverts to full speed default state if no downstream chirp is detected. Resolution of this parameter is 33.3 ns. For simulation purposes it is recommended to set the value 1000 [~33.3us] For synthesis purposes it is recommended to set the value 104963 [~3.5ms]
